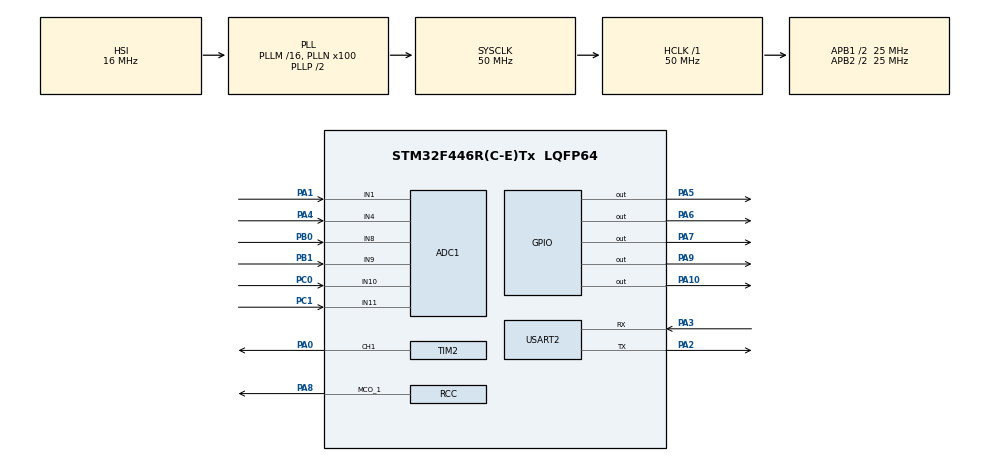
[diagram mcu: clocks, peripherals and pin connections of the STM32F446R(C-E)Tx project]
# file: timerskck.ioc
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ADC1.Channel-1\#ChannelRegularConversion=ADC_CHANNEL_1
ADC1.Channel-2\#ChannelRegularConversion=ADC_CHANNEL_1
ADC1.Channel-3\#ChannelRegularConversion=ADC_CHANNEL_1
ADC1.Channel-4\#ChannelRegularConversion=ADC_CHANNEL_1
ADC1.Channel-5\#ChannelRegularConversion=ADC_CHANNEL_1
ADC1.Channel-6\#ChannelRegularConversion=ADC_CHANNEL_1
ADC1.InjNumberOfConversion=0
ADC1.NbrOfConversion=6
ADC1.NbrOfConversionFlag=1
ADC1.Rank-1\#ChannelRegularConversion=1
ADC1.Rank-2\#ChannelRegularConversion=2
ADC1.Rank-3\#ChannelRegularConversion=3
ADC1.Rank-4\#ChannelRegularConversion=4
ADC1.Rank-5\#ChannelRegularConversion=5
ADC1.Rank-6\#ChannelRegularConversion=6
ADC1.SamplingTime-1\#ChannelRegularConversion=ADC_SAMPLETIME_480CYCLES
ADC1.SamplingTime-2\#ChannelRegularConversion=ADC_SAMPLETIME_480CYCLES
ADC1.SamplingTime-3\#ChannelRegularConversion=ADC_SAMPLETIME_480CYCLES
ADC1.SamplingTime-4\#ChannelRegularConversion=ADC_SAMPLETIME_480CYCLES
ADC1.SamplingTime-5\#ChannelRegularConversion=ADC_SAMPLETIME_480CYCLES
ADC1.SamplingTime-6\#ChannelRegularConversion=ADC_SAMPLETIME_480CYCLES
ADC1.ScanConvMode=ENABLE
ADC1.master=1
Dma.ADC1.0.Direction=DMA_PERIPH_TO_MEMORY
Dma.ADC1.0.FIFOMode=DMA_FIFOMODE_DISABLE
Dma.ADC1.0.Instance=DMA2_Stream0
Dma.ADC1.0.MemDataAlignment=DMA_MDATAALIGN_BYTE
Dma.ADC1.0.MemInc=DMA_MINC_ENABLE
Dma.ADC1.0.Mode=DMA_CIRCULAR
Dma.ADC1.0.PeriphDataAlignment=DMA_PDATAALIGN_BYTE
Dma.ADC1.0.PeriphInc=DMA_PINC_DISABLE
Dma.ADC1.0.Priority=DMA_PRIORITY_LOW
Dma.Request0=ADC1
Mcu.Family=STM32F4
Mcu.Name=STM32F446R(C-E)Tx
Mcu.Package=LQFP64
NVIC.ADC_IRQn=true\:1\:0\:true\:false\:true\:true\:true\:true
NVIC.DMA2_Stream0_IRQn=true\:0\:0\:false\:false\:true\:false\:true\:true
NVIC.PriorityGroup=NVIC_PRIORITYGROUP_4
NVIC.USART2_IRQn=true\:0\:0\:false\:false\:true\:true\:true\:true
PA0-WKUP.Signal=S_TIM2_CH1_ETR
PA1.Signal=ADCx_IN1
PA10.Signal=GPIO_Output
PA2.Mode=Asynchronous
PA2.Signal=USART2_TX
PA3.Mode=Asynchronous
PA3.Signal=USART2_RX
PA4.Signal=ADCx_IN4
PA5.Signal=GPIO_Output
PA6.Signal=GPIO_Output
PA7.Signal=GPIO_Output
PA8.Mode=Clock-out-1
PA8.Signal=RCC_MCO_1
PA9.Signal=GPIO_Output
PB0.Signal=ADCx_IN8
PB1.Signal=ADCx_IN9
PC0.Signal=ADCx_IN10
PC1.Signal=ADCx_IN11
PC14-OSC32_IN.Mode=LSE-External-Oscillator
PC14-OSC32_IN.Signal=RCC_OSC32_IN
PC15-OSC32_OUT.Mode=LSE-External-Oscillator
PC15-OSC32_OUT.Signal=RCC_OSC32_OUT
ProjectManager.HeapSize=0x200
ProjectManager.StackSize=0x400
ProjectManager.TargetToolchain=STM32CubeIDE
RCC.AHBFreq_Value=50000000
RCC.APB1CLKDivider=RCC_HCLK_DIV2
RCC.APB1Freq_Value=25000000
RCC.APB1TimFreq_Value=50000000
RCC.APB2CLKDivider=RCC_HCLK_DIV2
RCC.APB2Freq_Value=25000000
RCC.APB2TimFreq_Value=50000000
RCC.CortexFreq_Value=50000000
RCC.HCLKFreq_Value=50000000
RCC.PLLN=100
RCC.SYSCLKFreq_VALUE=50000000
RCC.SYSCLKSource=RCC_SYSCLKSOURCE_PLLCLK
RCC.USBFreq_Value=50000000
RCC.VCOOutputFreq_Value=100000000
SH.ADCx_IN1.0=ADC1_IN1,IN1
SH.ADCx_IN10.0=ADC1_IN10,IN10
SH.ADCx_IN11.0=ADC1_IN11,IN11
SH.ADCx_IN4.0=ADC1_IN4,IN4
SH.ADCx_IN8.0=ADC1_IN8,IN8
SH.ADCx_IN9.0=ADC1_IN9,IN9
SH.S_TIM2_CH1_ETR.0=TIM2_CH1,Output Compare1 CH1
TIM2.Channel-Output\ Compare1\ CH1=TIM_CHANNEL_1
TIM2.OCMode_1=TIM_OCMODE_TOGGLE
TIM2.Prescaler=1
TIM2.Pulse-Output\ Compare1\ CH1=25000
USART2.VirtualMode=VM_ASYNC
VP_TIM2_VS_ClockSourceINT.Mode=Internal
board=custom

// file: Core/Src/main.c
/* USER CODE BEGIN Header */
/**
  ******************************************************************************
  * @file           : main.c
  * @brief          : Main program body
  ******************************************************************************
  * @attention
  *
  * Copyright (c) 2023 STMicroelectronics.
  * All rights reserved.
  *
  * This software is licensed under terms that can be found in the LICENSE file
  * in the root directory of this software component.
  * If no LICENSE file comes with this software, it is provided AS-IS.
  *
  ******************************************************************************
  */
/* USER CODE END Header */
#include "main.h"

ADC_HandleTypeDef hadc1;
DMA_HandleTypeDef hdma_adc1;

TIM_HandleTypeDef htim2;

UART_HandleTypeDef huart2;

void SystemClock_Config(void);
static void MX_GPIO_Init(void);
static void MX_DMA_Init(void);
static void MX_TIM2_Init(void);
static void MX_USART2_UART_Init(void);
static void MX_ADC1_Init(void);
/* USER CODE BEGIN PFP */
void time();
/* USER CODE END PFP */

int main(void)
{

  /* MCU Configuration--------------------------------------------------------*/

  /* Reset of all peripherals, Initializes the Flash interface and the Systick. */
  HAL_Init();

  /* Configure the system clock */
  SystemClock_Config();

  /* USER CODE BEGIN SysInit */

  MX_GPIO_Init();
  MX_TIM2_Init();
  MX_USART2_UART_Init();
  MX_ADC1_Init();
  /* USER CODE END SysInit */

  /* Initialize all configured peripherals */
  MX_GPIO_Init();
  MX_DMA_Init();
  MX_TIM2_Init();
  MX_USART2_UART_Init();
  MX_ADC1_Init();
  /* USER CODE BEGIN 2 */
 //uint32_t t=  HAL_GetTick();
 uint8_t a[6];
  /* USER CODE END 2 */

  /* Infinite loop */
  /* USER CODE BEGIN WHILE */
 HAL_ADC_Start(&hadc1);
 HAL_ADC_PollForConversion(&hadc1, 10);
 HAL_ADC_Start_DMA(&hadc1, pData, Length);
 sprintf(q,"%d",val);

 	       HAL_UART_Transmit(&huart2, q, strlen(q), 10);
    /* USER CODE END WHILE */

}

void SystemClock_Config(void)
{
  RCC_OscInitTypeDef RCC_OscInitStruct = {0};
  RCC_ClkInitTypeDef RCC_ClkInitStruct = {0};

  /** Configure the main internal regulator output voltage
  */
  __HAL_RCC_PWR_CLK_ENABLE();
  __HAL_PWR_VOLTAGESCALING_CONFIG(PWR_REGULATOR_VOLTAGE_SCALE3);

  /** Initializes the RCC Oscillators according to the specified parameters
  * in the RCC_OscInitTypeDef structure.
  */
  RCC_OscInitStruct.OscillatorType = RCC_OSCILLATORTYPE_HSI;
  RCC_OscInitStruct.HSIState = RCC_HSI_ON;
  RCC_OscInitStruct.HSICalibrationValue = RCC_HSICALIBRATION_DEFAULT;
  RCC_OscInitStruct.PLL.PLLState = RCC_PLL_ON;
  RCC_OscInitStruct.PLL.PLLSource = RCC_PLLSOURCE_HSI;
  RCC_OscInitStruct.PLL.PLLM = 16;
  RCC_OscInitStruct.PLL.PLLN = 100;
  RCC_OscInitStruct.PLL.PLLP = RCC_PLLP_DIV2;
  RCC_OscInitStruct.PLL.PLLQ = 2;
  RCC_OscInitStruct.PLL.PLLR = 2;
  if (HAL_RCC_OscConfig(&RCC_OscInitStruct) != HAL_OK)
  {
    Error_Handler();
  }

  /** Initializes the CPU, AHB and APB buses clocks
  */
  RCC_ClkInitStruct.ClockType = RCC_CLOCKTYPE_HCLK|RCC_CLOCKTYPE_SYSCLK
                              |RCC_CLOCKTYPE_PCLK1|RCC_CLOCKTYPE_PCLK2;
  RCC_ClkInitStruct.SYSCLKSource = RCC_SYSCLKSOURCE_PLLCLK;
  RCC_ClkInitStruct.AHBCLKDivider = RCC_SYSCLK_DIV1;
  RCC_ClkInitStruct.APB1CLKDivider = RCC_HCLK_DIV2;
  RCC_ClkInitStruct.APB2CLKDivider = RCC_HCLK_DIV2;

  if (HAL_RCC_ClockConfig(&RCC_ClkInitStruct, FLASH_LATENCY_1) != HAL_OK)
  {
    Error_Handler();
  }
  HAL_RCC_MCOConfig(RCC_MCO1, RCC_MCO1SOURCE_HSI, RCC_MCODIV_1);
}

static void MX_ADC1_Init(void)
{

  ADC_ChannelConfTypeDef sConfig = {0};

  /** Configure the global features of the ADC (Clock, Resolution, Data Alignment and number of conversion)
  */
  hadc1.Instance = ADC1;
  hadc1.Init.ClockPrescaler = ADC_CLOCK_SYNC_PCLK_DIV2;
  hadc1.Init.Resolution = ADC_RESOLUTION_12B;
  hadc1.Init.ScanConvMode = ENABLE;
  hadc1.Init.ContinuousConvMode = DISABLE;
  hadc1.Init.DiscontinuousConvMode = DISABLE;
  hadc1.Init.ExternalTrigConvEdge = ADC_EXTERNALTRIGCONVEDGE_NONE;
  hadc1.Init.ExternalTrigConv = ADC_SOFTWARE_START;
  hadc1.Init.DataAlign = ADC_DATAALIGN_RIGHT;
  hadc1.Init.NbrOfConversion = 6;
  hadc1.Init.DMAContinuousRequests = DISABLE;
  hadc1.Init.EOCSelection = ADC_EOC_SINGLE_CONV;
  if (HAL_ADC_Init(&hadc1) != HAL_OK)
  {
    Error_Handler();
  }

  /** Configure for the selected ADC regular channel its corresponding rank in the sequencer and its sample time.
  */
  sConfig.Channel = ADC_CHANNEL_1;
  sConfig.Rank = 1;
  sConfig.SamplingTime = ADC_SAMPLETIME_480CYCLES;
  if (HAL_ADC_ConfigChannel(&hadc1, &sConfig) != HAL_OK)
  {
    Error_Handler();
  }

  /** Configure for the selected ADC regular channel its corresponding rank in the sequencer and its sample time.
  */
  sConfig.Rank = 2;
  if (HAL_ADC_ConfigChannel(&hadc1, &sConfig) != HAL_OK)
  {
    Error_Handler();
  }

  /** Configure for the selected ADC regular channel its corresponding rank in the sequencer and its sample time.
  */
  sConfig.Rank = 3;
  if (HAL_ADC_ConfigChannel(&hadc1, &sConfig) != HAL_OK)
  {
    Error_Handler();
  }

  /** Configure for the selected ADC regular channel its corresponding rank in the sequencer and its sample time.
  */
  sConfig.Rank = 4;
  if (HAL_ADC_ConfigChannel(&hadc1, &sConfig) != HAL_OK)
  {
    Error_Handler();
  }

  /** Configure for the selected ADC regular channel its corresponding rank in the sequencer and its sample time.
  */
  sConfig.Rank = 5;
  if (HAL_ADC_ConfigChannel(&hadc1, &sConfig) != HAL_OK)
  {
    Error_Handler();
  }

  /** Configure for the selected ADC regular channel its corresponding rank in the sequencer and its sample time.
  */
  sConfig.Rank = 6;
  if (HAL_ADC_ConfigChannel(&hadc1, &sConfig) != HAL_OK)
  {
    Error_Handler();
  }

}

static void MX_TIM2_Init(void)
{

  TIM_ClockConfigTypeDef sClockSourceConfig = {0};
  TIM_MasterConfigTypeDef sMasterConfig = {0};
  TIM_OC_InitTypeDef sConfigOC = {0};

  htim2.Instance = TIM2;
  htim2.Init.Prescaler = 1;
  htim2.Init.CounterMode = TIM_COUNTERMODE_UP;
  htim2.Init.Period = 4294967295;
  htim2.Init.ClockDivision = TIM_CLOCKDIVISION_DIV1;
  htim2.Init.AutoReloadPreload = TIM_AUTORELOAD_PRELOAD_DISABLE;
  if (HAL_TIM_Base_Init(&htim2) != HAL_OK)
  {
    Error_Handler();
  }
  sClockSourceConfig.ClockSource = TIM_CLOCKSOURCE_INTERNAL;
  if (HAL_TIM_ConfigClockSource(&htim2, &sClockSourceConfig) != HAL_OK)
  {
    Error_Handler();
  }
  if (HAL_TIM_OC_Init(&htim2) != HAL_OK)
  {
    Error_Handler();
  }
  sMasterConfig.MasterOutputTrigger = TIM_TRGO_RESET;
  sMasterConfig.MasterSlaveMode = TIM_MASTERSLAVEMODE_DISABLE;
  if (HAL_TIMEx_MasterConfigSynchronization(&htim2, &sMasterConfig) != HAL_OK)
  {
    Error_Handler();
  }
  sConfigOC.OCMode = TIM_OCMODE_TOGGLE;
  sConfigOC.Pulse = 25000;
  sConfigOC.OCPolarity = TIM_OCPOLARITY_HIGH;
  sConfigOC.OCFastMode = TIM_OCFAST_DISABLE;
  if (HAL_TIM_OC_ConfigChannel(&htim2, &sConfigOC, TIM_CHANNEL_1) != HAL_OK)
  {
    Error_Handler();
  }
  /* USER CODE BEGIN TIM2_Init 2 */
  if(HAL_TIM_PWM_ConfigChannel(&htim2,  &sConfigOC,TIM_CHANNEL_1)!=HAL_OK){
 	  Error_Handler();
   }
  /* USER CODE END TIM2_Init 2 */
  HAL_TIM_MspPostInit(&htim2);

}

static void MX_USART2_UART_Init(void)
{

  huart2.Instance = USART2;
  huart2.Init.BaudRate = 115200;
  huart2.Init.WordLength = UART_WORDLENGTH_8B;
  huart2.Init.StopBits = UART_STOPBITS_1;
  huart2.Init.Parity = UART_PARITY_NONE;
  huart2.Init.Mode = UART_MODE_TX_RX;
  huart2.Init.HwFlowCtl = UART_HWCONTROL_NONE;
  huart2.Init.OverSampling = UART_OVERSAMPLING_16;
  if (HAL_UART_Init(&huart2) != HAL_OK)
  {
    Error_Handler();
  }

}

static void MX_DMA_Init(void)
{

  /* DMA controller clock enable */
  __HAL_RCC_DMA2_CLK_ENABLE();

  /* DMA interrupt init */
  /* DMA2_Stream0_IRQn interrupt configuration */
  HAL_NVIC_SetPriority(DMA2_Stream0_IRQn, 0, 0);
  HAL_NVIC_EnableIRQ(DMA2_Stream0_IRQn);

}

static void MX_GPIO_Init(void)
{
  GPIO_InitTypeDef GPIO_InitStruct = {0};

  /* GPIO Ports Clock Enable */
  __HAL_RCC_GPIOC_CLK_ENABLE();
  __HAL_RCC_GPIOA_CLK_ENABLE();
  __HAL_RCC_GPIOB_CLK_ENABLE();

  /*Configure GPIO pin Output Level */
  HAL_GPIO_WritePin(GPIOA, GPIO_PIN_5|GPIO_PIN_6|GPIO_PIN_7|GPIO_PIN_9
                          |GPIO_PIN_10, GPIO_PIN_RESET);

  /*Configure GPIO pins : PA5 PA6 PA7 PA9
                           PA10 */
  GPIO_InitStruct.Pin = GPIO_PIN_5|GPIO_PIN_6|GPIO_PIN_7|GPIO_PIN_9
                          |GPIO_PIN_10;
  GPIO_InitStruct.Mode = GPIO_MODE_OUTPUT_PP;
  GPIO_InitStruct.Pull = GPIO_NOPULL;
  GPIO_InitStruct.Speed = GPIO_SPEED_FREQ_LOW;
  HAL_GPIO_Init(GPIOA, &GPIO_InitStruct);

  /*Configure GPIO pin : PA8 */
  GPIO_InitStruct.Pin = GPIO_PIN_8;
  GPIO_InitStruct.Mode = GPIO_MODE_AF_PP;
  GPIO_InitStruct.Pull = GPIO_NOPULL;
  GPIO_InitStruct.Speed = GPIO_SPEED_FREQ_LOW;
  GPIO_InitStruct.Alternate = GPIO_AF0_MCO;
  HAL_GPIO_Init(GPIOA, &GPIO_InitStruct);

}

void Error_Handler(void)
{
  __disable_irq();
  while (1)
  {
  }
}
